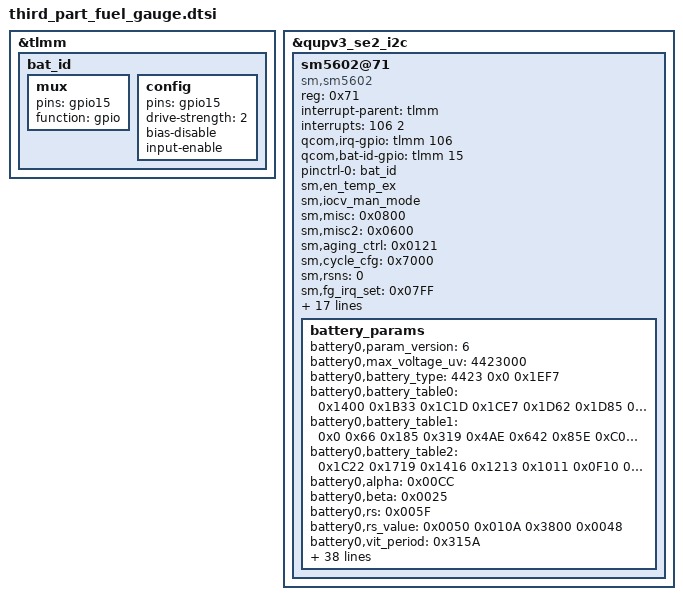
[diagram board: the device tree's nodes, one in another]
/*
 * Copyright (C) 2018 CNCE Inc.
 *
 * This program is free software; you can redistribute it and/or modify
 * it under the terms of the GNU General Public License version 2 as
 * published by the Free Software Foundation.
 *
 * This program is distributed in the hope that it will be useful,
 * but WITHOUT ANY WARRANTY; without even the implied warranty of
 * MERCHANTABILITY or FITNESS FOR A PARTICULAR PURPOSE.
 * See http://www.gnu.org/licenses/gpl-2.0.html for more details.
 */

&tlmm {
	bat_id: bat_id {
		mux {
			pins = "gpio15";
			function = "gpio";
		};

		config {
			pins = "gpio15";
			drive-strength = <2>;
			bias-disable;
			input-enable;
		};
	};
};

&qupv3_se2_i2c {
	status = "ok";
	sm5602@71 {
		compatible = "sm,sm5602";
		reg = <0x71>;
		interrupt-parent = <&tlmm>;
		interrupts = <106 2>;
		qcom,irq-gpio = <&tlmm 106 0x0>;

		/* bat id setting */
		qcom,bat-id-gpio = <&tlmm 15 0x00>;
		pinctrl-names = "default";
		pinctrl-0 = <&bat_id>;

		sm,en_temp_ex;
		//sm,en_temp_in;
		//sm,en_temp_3rd;
		//sm,en_batt_det;
		sm,iocv_man_mode;
		sm,misc = <0x0800>;
		sm,misc2 = <0x0600>;
		sm,aging_ctrl = <0x0121>;
		sm,cycle_cfg = <0x7000>;
		sm,rsns = <0>;
		sm,fg_irq_set = <0x07FF>;
		sm,low_soc1 = <1>;
		sm,low_soc2 = <15>;
		sm,v_l_alarm = <3400>;
		sm,v_h_alarm = <4450>;
		sm,battery_table_num = <0>;
		sm,param_version = <6>;
		sm,t_l_alarm_in = <54>;
		sm,t_h_alarm_in = <1>;
		sm,t_l_alarm_ex = <0xD3D8>;
		sm,t_h_alarm_ex = <0x9245>;
		sm,shutdown-delay-enable;
		sm,rtrace = <0>;
		sm,rpara = <0x0>;
		sm,curr_voffset = <0>;
		sm,curr_vslope = <0x8080>;
		/* 1degree mA */
		//temp-compensation = <2 2500
		//                     4 3500 >;
		sm,t_h_alarm_temp = <55>;
		sm,t_l_alarm_temp = <0>;
		battery_params {
			battery0,param_version = <6>;
			battery0,max_voltage_uv = <4423000>;
			battery0,battery_type = <4423 0x0 0x1EF7>;
			battery0,battery_table0 = <0x1400 0x1B33 0x1C1D 0x1CE7 0x1D62 0x1D85 0x1D8E 0x1D9A 0x1DDE 0x1E24 0x1E69 0x1EA1 0x1EED 0x1F30 0x1F5F 0x1FDD 0x2046 0x20B0 0x2123 0x21DD 0x2236 0x22DB 0x231E 0x24CC>;
			battery0,battery_table1 = <0x0 0x66 0x185 0x319 0x4AE 0x642 0x85E 0xC0D 0x1152 0x1938 0x211E 0x2904 0x30EA 0x362F 0x38D1 0x3E15 0x4359 0x489D 0x4DE1 0x55C7 0x5977 0x60D7 0x6400 0x64E6>;
			battery0,battery_table2 = <0x1C22 0x1719 0x1416 0x1213 0x1011 0x0F10 0x0F0F 0x0E0E>;
			battery0,alpha = <0x00CC>;
			battery0,beta = <0x0025>;
			battery0,rs = <0x005F>;
			battery0,rs_value = <0x0050 0x010A 0x3800 0x0048>;
			battery0,vit_period = <0x315A>;
			battery0,volt_cal = <0x8000>;
			battery0,mix_value = <0x0003>;
			battery0,curr_offset = <0x000>;
			battery0,curr_slope = <0x8080>;
			battery0,topoff_soc = <7 280 100>;
			battery0,temp_std = <25>;
			battery0,temp_offset = <0 11 1 0 8 (-1)>;
			battery0,temp_cal = <0 6 1 11 (-1) 0 6 1 9 1>;
			battery0,ext_temp_cal = <0 2 1 2 1 1 2 3 2 3>;
			battery0,tem_poff = <3400 100>;
			battery0,thermal_table = <0x6F1A 0x697F 0x63F4 0x5E67 0x58F3 0x537E 0x4E28 0x48D5 0x43B2 0x3E98
									0x3993 0x34A6 0x2FD1 0x2B1A 0x2678 0x21E2 0x1D77 0x1905 0x14ED 0x10FB 
									0x0CF1 0x090F 0x053D 0x017B 0xF5AA 0xF23C 0xEEC9 0xEB72 0xE844 0xE52C 
									0xE22D 0xDF4A 0xDC80 0xD9CB 0xD72D 0xD4A1 0xD231 0xCFD1 0xCD87 0xCB50 
									0xC92E 0xC721 0xC523 0xC335 0xC15B 0xBF90 0xBDD5 0xBC2A 0xBA8F 0xB901 
									0xB784 0xB613 0xB4AF 0xB35A 0xB20E 0xB0CB 0xAF9B 0xAE72 0xAD52 0xAC3C 
									0xAB31 0xAA33 0xA93B 0xA84D 0xA764 0xA684 0xA5B0 0xA4E2 0xA41E 0xA35A 
									0xA2A5 0xA1F3 0xA146 0xA09F 0xA002 0x9F68 0x9ED2 0x9E3E 0x9DB2 0x9D2D 
									0x9CAD 0x9C31 0x9BB6 0x9B40 0x9AD0 0x9A64 0x99FB 0x9995 0x9935 0x98D8 
									0x987D 0x9824 0x97CF 0x977E 0x9731 0x96E5 0x969D 0x9656 0x9612 0x95D0 
									0x9590 0x9551 0x9515 0x94DA 0x94A2 0x946B>;  //NTC value(DEC) table -30~75, 110K PU/10k NTC
			battery1,param_version = <7>;
			battery1,max_voltage_uv = <4423000>;
			battery1,battery_type = <4423 0x0 0x1EC6>;
			battery1,battery_table0 = <0x1400 0x1B32 0x1BF8 0x1CD5 0x1D5F 0x1D85 0x1D8D 0x1D9E 0x1DE2 0x1E27 0x1E65 0x1EB1 0x1F06 0x1F5D 0x1FB2 0x1FE1 0x203F 0x20A9 0x211C 0x21D4 0x222E 0x22D3 0x2317 0x24CC>;
			battery1,battery_table1 = <0x0 0x66 0x148 0x2DC 0x46F 0x689 0x8A2 0xC4F 0x118F 0x1970 0x2150 0x2BD1 0x33B1 0x38F1 0x3B91 0x3E31 0x4371 0x48B2 0x4DF2 0x55D2 0x597F 0x60D9 0x6400 0x64E6>;
			battery1,battery_table2 = <0x1D24 0x181A 0x1517 0x1314 0x1112 0x1011 0x1010 0x0E0E>;
			battery1,alpha = <0x00CC>;
			battery1,beta = <0x0025>;
			battery1,rs = <0x005F>;
			battery1,rs_value = <0x0050 0x010A 0x3800 0x0048>;
			battery1,vit_period = <0x315A>;
			battery1,volt_cal = <0x8000>;
			battery1,mix_value = <0x0003>;
			battery1,curr_offset = <0x000>;
			battery1,curr_slope = <0x8080>;
			battery1,topoff_soc = <7 280 100>;
			battery1,temp_std = <25>;
			battery1,temp_offset = <0 11 1 0 8 (-1)>;
			battery1,temp_cal = <0 6 1 11 (-1) 0 6 1 9 1>;
			battery1,ext_temp_cal = <0 2 1 2 1 1 2 3 2 3>;
			battery1,tem_poff = <3400 100>;
			battery1,thermal_table = <0x6F1A 0x697F 0x63F4 0x5E67 0x58F3 0x537E 0x4E28 0x48D5 0x43B2 0x3E98
									0x3993 0x34A6 0x2FD1 0x2B1A 0x2678 0x21E2 0x1D77 0x1905 0x14ED 0x10FB 
									0x0CF1 0x090F 0x053D 0x017B 0xF5AA 0xF23C 0xEEC9 0xEB72 0xE844 0xE52C 
									0xE22D 0xDF4A 0xDC80 0xD9CB 0xD72D 0xD4A1 0xD231 0xCFD1 0xCD87 0xCB50 
									0xC92E 0xC721 0xC523 0xC335 0xC15B 0xBF90 0xBDD5 0xBC2A 0xBA8F 0xB901 
									0xB784 0xB613 0xB4AF 0xB35A 0xB20E 0xB0CB 0xAF9B 0xAE72 0xAD52 0xAC3C 
									0xAB31 0xAA33 0xA93B 0xA84D 0xA764 0xA684 0xA5B0 0xA4E2 0xA41E 0xA35A 
									0xA2A5 0xA1F3 0xA146 0xA09F 0xA002 0x9F68 0x9ED2 0x9E3E 0x9DB2 0x9D2D 
									0x9CAD 0x9C31 0x9BB6 0x9B40 0x9AD0 0x9A64 0x99FB 0x9995 0x9935 0x98D8 
									0x987D 0x9824 0x97CF 0x977E 0x9731 0x96E5 0x969D 0x9656 0x9612 0x95D0 
									0x9590 0x9551 0x9515 0x94DA 0x94A2 0x946B>;  //NTC value(DEC) table -30~75, 110K PU/10k NTC	
	    };
	};	
};
